# GD32VW553x register map
Vendor: GigaDevice; File version: 1.0
CPU: OTHER r0p0, little endian, no MPU, no FPU, 4 interrupt priority bits
Registers are 32-bit, read-write, reset 0x0 unless marked. A register's access mark holds for its fields unless they carry their own. Offsets are from the block's base; [hi:lo] are bit positions; {n}, {i} and the like mark numbered series.

## CAU — Cryptographic Acceleration Unit
Base 0x4C060000
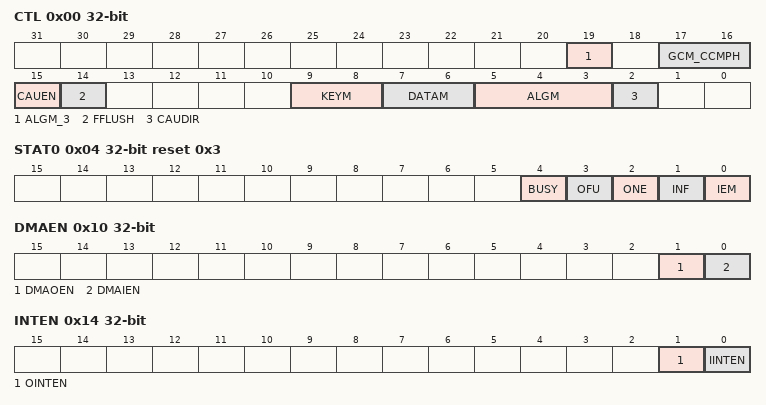
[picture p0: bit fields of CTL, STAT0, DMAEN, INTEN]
0x00 CTL — Control register
  [19] ALGM_3 — Encryption / decryption algorithm mode bit 3
  [17:16] GCM_CCMPH — GCM CCM phase
  [15] CAUEN — CAU Enable
  [14] FFLUSH wo — Flush FIFO
  [9:8] KEYM — AES key size mode configuration, must be configured when BUSY = 0
  [7:6] DATAM — Data swapping type mode configuration, must be configured when BUSY = 0
  [5:3] ALGM — Encryption / decryption algorithm mode bit 0 to bit 2
  [2] CAUDIR — CAU direction, must be configured when BUSY = 0
0x04 STAT0 reset 0x3 — Status register 0
  [4] BUSY ro — Busy bit
  [3] OFU ro — Output FIFO is full
  [2] ONE ro — Output FIFO is not empty
  [1] INF ro — Input FIFO is not full
  [0] IEM ro — Input FIFO is empty
0x08 DI — Data input register
  [31:0] DI — Datainput
0x0C DO — Data output register
  [31:0] DO ro — Data output
0x10 DMAEN — DMA enable register
  [1] DMAOEN — DMA output enable
  [0] DMAIEN — DMA input enable
0x14 INTEN — Interrupt enable register
  [1] OINTEN — OUT FIFO interrupt enable
  [0] IINTEN — IN FIFO interrupt enable
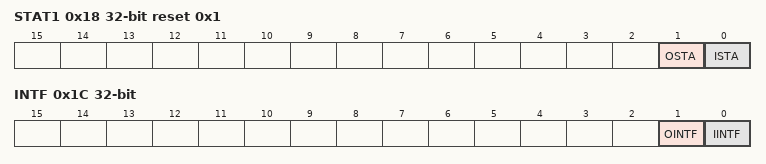
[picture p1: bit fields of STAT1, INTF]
0x18 STAT1 reset 0x1 — Status register 1
  [1] OSTA ro — OUT FIFO interrupt status
  [0] ISTA ro — IN FIFO interrupt status
0x1C INTF — Interrupt flag register
  [1] OINTF ro — OUT FIFO enabled interrupt flag
  [0] IINTF ro — IN FIFO enabled interrupt flag
{0x20+8i} KEY{i}H (i=0..3) — KEY{i} high register
  [31:0] KEY{i}H wo — The key for DES, TDES, AES
{0x24+8i} KEY{i}L (i=0..3) — KEY{i} low register
  [31:0] KEY{i}L wo — The key for DES, TDES, AES
0x40 IV0H — Initial vector registers 0 high
  [31:0] IV0H — The initialization vector for DES, TDES, AES
0x44 IV0L — Initial vector registers 0 low
  [31:0] IV0L — The initialization vector for DES, TDES, AES
0x48 IV1H — Initial vector registers 1 high
  [31:0] IV1H — The initialization vector for DES, TDES, AES
0x4C IV1L — Initial vector registers 1 low
  [31:0] IV1L — The initialization vector for DES, TDES, AES
{0x50+4i} GCMCCMCTXS{i} (i=0..7) — GCM or CCM mode context switch register {i}
  [31:0] CTXx — The internal status of the CAU core
{0x70+4i} GCMCTXS{i} (i=0..7) — GCM mode context switch register {i}
  [31:0] CTXx — The internal status of the CAU core

## CPU_TIMER
Base 0xD1000000
0x00 MTIME_LO — mtime low register
  [31:0] COUNT — MTIME count
0x04 MTIME_HI — mtime high register
  [31:0] COUNT — MTIME count
0x08 MTIMECMP_LO reset 0xFFFFFFFF — mtimecmp low register
  [31:0] COUNT — MTIMECMP count
0x0C MTIMECMP_HI reset 0xFFFFFFFF — mtimecmp high register
  [31:0] COUNT — MTIMECMP count
0xFF0 MSFTRST — Generate soft-reset request
  [31] MSFTRST — This bit is used to generate the Soft-Reset Request
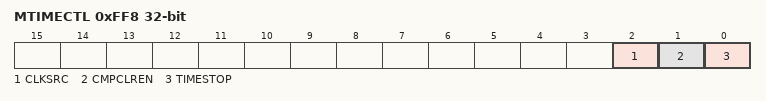
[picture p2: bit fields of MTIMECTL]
0xFF8 MTIMECTL — Control some features of the time counter
  [2] CLKSRC — Select the source of increment frequency
  [1] CMPCLREN — Control the timer count to clear-to-zero or not
  [0] TIMESTOP — Control the timer count or pause
0xFFC MSIP
  [0] MSIP — This bit is used to generate the software interrupt

## CRC — Cyclic redundancy checks management unit
Base 0x40023000
0x00 DATA reset 0xFFFFFFFF
  [31:0] DATA — CRC calculation result bits
0x04 FDATA — Free data register
  [7:0] FDATA — Free Data Register bits
0x08 CTL — Control register
  [0] RST ro — reset the CRC_DATA register

## DBG — Debug
Base 0xE0044000
0x00 ID — ID code register
  [31:0] ID_CODE ro — DBG ID code register
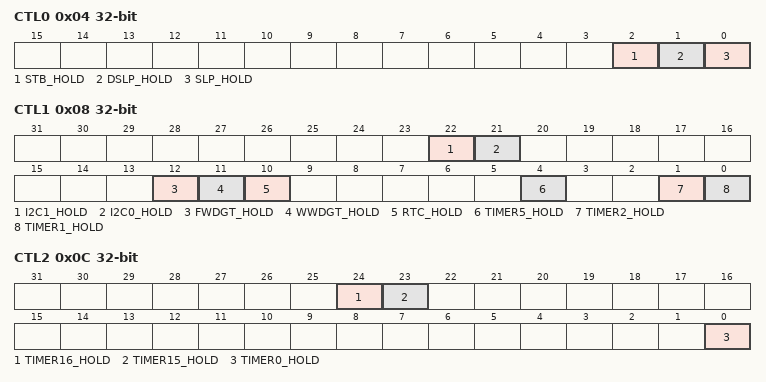
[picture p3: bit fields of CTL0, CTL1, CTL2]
0x04 CTL0 — Control register 0
  [2] STB_HOLD — Standby mode hold bit
  [1] DSLP_HOLD — Deep-sleep mode hold bit
  [0] SLP_HOLD — Sleep mode hold bit
0x08 CTL1 — Control register 1
  [22] I2C1_HOLD — I2C1 hold bit
  [21] I2C0_HOLD — I2C0 hold bit
  [12] FWDGT_HOLD — FWDGT hold bit
  [11] WWDGT_HOLD — WWDGT hold bit
  [10] RTC_HOLD — RTC hold bit
  [4] TIMER5_HOLD — TIMER5 hold bit
  [1] TIMER2_HOLD — TIMER2 hold bit
  [0] TIMER1_HOLD — TIMER1 hold bit
0x0C CTL2 — Control register 2
  [24] TIMER16_HOLD — TIMER16 hold bit
  [23] TIMER15_HOLD — TIMER15 hold bit
  [0] TIMER0_HOLD — TIMER0 hold bit
